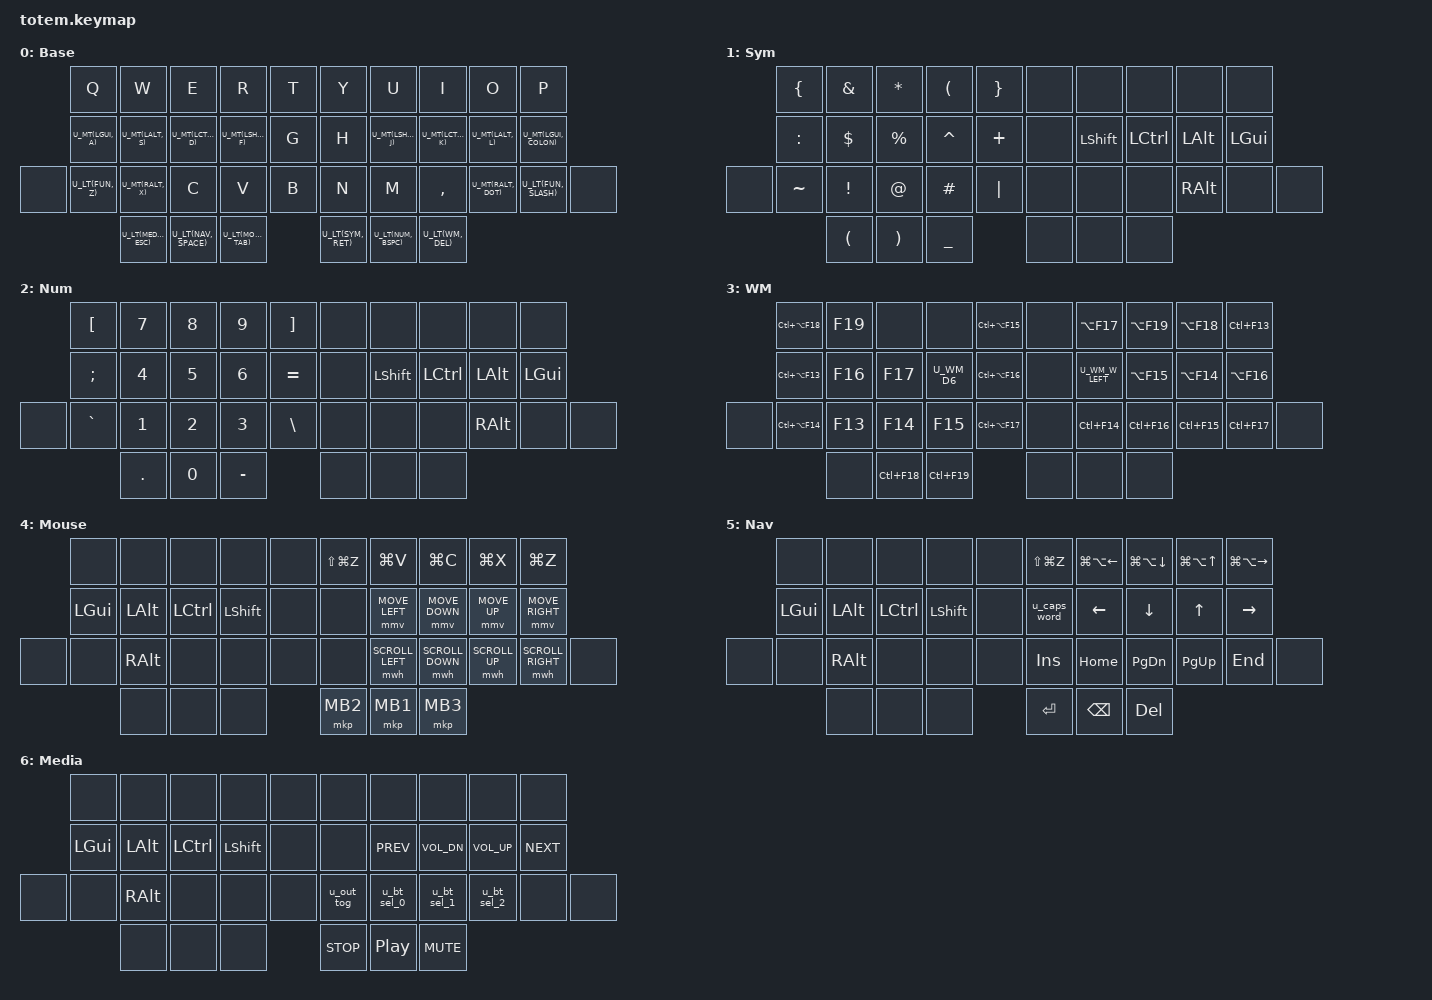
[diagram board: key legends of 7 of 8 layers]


#include <behaviors.dtsi>
#include <dt-bindings/zmk/keys.h>
#include <dt-bindings/zmk/bt.h>
#include <dt-bindings/zmk/outputs.h>
#include <dt-bindings/zmk/mouse.h>

// ⎯⎯⎯⎯⎯⎯⎯⎯⎯⎯⎯⎯⎯⎯⎯⎯⎯⎯⎯⎯⎯⎯⎯⎯⎯⎯⎯⎯⎯⎯⎯⎯⎯⎯⎯⎯⎯⎯⎯⎯⎯⎯⎯⎯⎯⎯⎯⎯⎯⎯⎯⎯⎯⎯⎯⎯⎯⎯⎯⎯⎯⎯⎯⎯⎯⎯⎯⎯⎯⎯⎯⎯⎯⎯⎯⎯⎯⎯⎯⎯⎯⎯⎯⎯⎯⎯⎯⎯⎯⎯

// Layers
#define BASE  0
#define SYM   1
#define NUM   2
#define WM    3
#define MOUSE 4
#define NAV   5
#define MEDIA 6
#define FUN   7

// Behaviors
#define U_NA &none
#define U_MT(MOD, TAP) &u_mt MOD TAP
#define U_LT(LAYER, TAP) &u_lt LAYER TAP

// Clipboard
#define U_RDO &kp LS(LG(Z))
#define U_PST &kp LG(V)
#define U_CPY &kp LG(C)
#define U_CUT &kp LG(X)
#define U_UND &kp LG(Z)

// Mouse key
#define U_MOUSE_MOVE_MAX 1250
#define U_MOUSE_MOVE_EXPONENT 1
#define U_MOUSE_MOVE_TIME 1500
#define U_MOUSE_MOVE_DELAY 0
#define U_MOUSE_SCROLL_MAX 100
#define U_MOUSE_SCROLL_EXPONENT 1
#define U_MOUSE_SCROLL_TIME 5000
#define U_MOUSE_SCROLL_DELAY 0

#undef MOVE_UP
#undef MOVE_DOWN
#undef MOVE_LEFT
#undef MOVE_RIGHT
#undef SCROLL_UP
#undef SCROLL_DOWN
#undef SCROLL_LEFT
#undef SCROLL_RIGHT
#define MOVE_UP MOVE_VERT(-U_MOUSE_MOVE_MAX)
#define MOVE_DOWN MOVE_VERT(U_MOUSE_MOVE_MAX)
#define MOVE_LEFT MOVE_HOR(-U_MOUSE_MOVE_MAX)
#define MOVE_RIGHT MOVE_HOR(U_MOUSE_MOVE_MAX)
#define SCROLL_UP SCROLL_VERT(U_MOUSE_SCROLL_MAX)
#define SCROLL_DOWN SCROLL_VERT(-U_MOUSE_SCROLL_MAX)
#define SCROLL_LEFT SCROLL_HOR(-U_MOUSE_SCROLL_MAX)
#define SCROLL_RIGHT SCROLL_HOR(U_MOUSE_SCROLL_MAX)

#define U_BTN1 &mkp MB1
#define U_BTN2 &mkp MB2
#define U_BTN3 &mkp MB3
#define U_MS_D &mmv MOVE_DOWN
#define U_MS_L &mmv MOVE_LEFT
#define U_MS_R &mmv MOVE_RIGHT
#define U_MS_U &mmv MOVE_UP
#define U_WH_D &mwh SCROLL_DOWN
#define U_WH_L &mwh SCROLL_LEFT
#define U_WH_R &mwh SCROLL_RIGHT
#define U_WH_U &mwh SCROLL_UP


&mmv {
  acceleration-exponent = <U_MOUSE_MOVE_EXPONENT>;
  time-to-max-speed-ms = <U_MOUSE_MOVE_TIME>;
  delay-ms = <U_MOUSE_MOVE_DELAY>;
};

// WM
#define U_WM_D1 &kp F13 // Focus to desktop 1
#define U_WM_D2 &kp F14 // Focus to desktop 2
#define U_WM_D3 &kp F15 // Focus to desktop 3
#define U_WM_D4 &kp F16 // Focus to desktop 4
#define U_WM_D5 &kp F17 // Focus to desktop 5
#define U_WM_D6 U_MT(LSHIFT, F18) // Focus to desktop 6
#define U_WM_D7 &kp F19 // Focus to desktop 7

#define U_WM_W_LEFT U_MT(LSHIFT, LA(F13)) // Focus to window left
#define U_WM_W_UP &kp LA(F14) // Focus to window up
#define U_WM_W_DOWN &kp LA(F15) // Focus to window down
#define U_WM_W_RIGHT &kp LA(F16) // Focus to window right

#define U_WM_DIS_LEFT &kp LA(F17) // Focus to display left
#define U_WM_DIS_UP &kp LA(F18) // Focus to display up
#define U_WM_DIS_DOWN &kp LA(F19) // Focus to display down
#define U_WM_DIS_RIGHT &kp LC(F13) // Focus to display right

#define U_WM_W_SIZE_LEFT &kp LC(F14) // Increase window size left
#define U_WM_W_SIZE_UP &kp LC(F15) // Increase window size up
#define U_WM_W_SIZE_DOWN &kp LC(F16) // Increase window size down
#define U_WM_W_SIZE_RIGHT &kp LC(F17) // Increase window size right

#define U_WM_D_LEFT &kp LC(F18) // Focus to previous desktop
#define U_WM_D_RIGHT &kp LC(F19) // Focus to next desktop

#define U_WM_X_MIRROR &kp LC(LA(F13)) // Mirror window horizontally
#define U_WM_Y_MIRROR &kp LC(LA(F14)) // Mirror window vertically
#define U_WM_W_ROTATE_CW &kp LC(LA(F15)) // Rotate window clockwise
#define U_WM_W_FLOAT_GRID &kp LC(LA(F16)) // Toggle window float/grid
#define U_WM_W_MAX &kp LC(LA(F17)) // Toggle window maximum
#define U_WM_W_BALANCE &kp LC(LA(F18)) // Toggle window maximum


#define U_TAPPING_TERM 200


/ {
    behaviors {
        u_mt: u_mt {
            compatible = "zmk,behavior-hold-tap";
            label = "u_mt";
            #binding-cells = <2>;
            tapping_term_ms = <U_TAPPING_TERM>;
            flavor = "tap-preferred";
            bindings = <&kp>, <&kp>;
        };
        u_lt: u_lt {
            compatible = "zmk,behavior-hold-tap";
            label = "u_lt";
            #binding-cells = <2>;
            tapping_term_ms = <U_TAPPING_TERM>;
            flavor = "tap-preferred";
            bindings = <&mo>, <&kp>;
        };

        // Shift functions
        u_caps_word: u_caps_word { 
            compatible = "zmk,behavior-mod-morph";
            label = "u_caps_word";
            #binding-cells = <0>;
            bindings = <&caps_word>, <&kp CAPS>;
            mods = <(MOD_LSFT|MOD_RSFT)>;
        };
        u_out_tog: u_out_tog { 
            compatible = "zmk,behavior-mod-morph";
            label = "u_out_tog";
            #binding-cells = <0>;
            bindings = <&out OUT_TOG>, <&out OUT_USB>;
            mods = <(MOD_LSFT|MOD_RSFT)>;
        };
        u_bt_sel_0: u_bt_sel_0 { 
            compatible = "zmk,behavior-mod-morph";
            label = "u_bt_sel_0";
            #binding-cells = <0>;
            bindings = <&bt BT_SEL 0>, <&u_macro_u_bt_sel_0>;
            mods = <(MOD_LSFT|MOD_RSFT)>;
        };
        u_bt_sel_1: u_bt_sel_1 { 
            compatible = "zmk,behavior-mod-morph";
            label = "u_bt_sel_1";
            #binding-cells = <0>;
            bindings = <&bt BT_SEL 1>, <&u_macro_u_bt_sel_0>;
            mods = <(MOD_LSFT|MOD_RSFT)>;
        };
        u_bt_sel_2: u_bt_sel_2 { 
            compatible = "zmk,behavior-mod-morph";
            label = "u_bt_sel_2";
            #binding-cells = <0>;
            bindings = <&bt BT_SEL 2>, <&u_macro_u_bt_sel_0>;
            mods = <(MOD_LSFT|MOD_RSFT)>;
        };
    };


    // combos {
    //     compatible = "zmk,combos";

    // };


    macros {
        u_macro_btn1: u_macro_btn1 {
            label = "u_macro_btn1";
            compatible = "zmk,behavior-macro";
            #binding-cells = <0>;
            wait-ms = <0>;
            bindings = <&kp KP_SLASH &kp KP_N5>;
        };

        u_macro_btn2: u_macro_btn2 {
            label = "u_macro_btn2";
            compatible = "zmk,behavior-macro";
            #binding-cells = <0>;
            wait-ms = <0>;
            bindings = <&kp KP_MINUS &kp KP_N5>;
        };

        u_macro_btn3: u_macro_btn3 {
            label = "u_macro_btn3";
            compatible = "zmk,behavior-macro";
            #binding-cells = <0>;
            wait-ms = <0>;
            bindings = <&kp KP_ASTERISK &kp KP_N5>;
        };

        u_macro_u_bt_sel_0: u_macro_u_bt_sel_0 {
            label = "u_macro_u_bt_sel_0";
            compatible = "zmk,behavior-macro";
            #binding-cells = <0>;
            wait-ms = <0>;
            bindings = <&bt BT_SEL 0 &bt BT_CLR>;
        };

        u_macro_u_bt_sel_1: u_macro_u_bt_sel_1 {
            label = "u_macro_u_bt_sel_1";
            compatible = "zmk,behavior-macro";
            #binding-cells = <0>;
            wait-ms = <0>;
            bindings = <&bt BT_SEL 1 &bt BT_CLR>;
        };

        u_macro_u_bt_sel_2: u_macro_u_bt_sel_2 {
            label = "u_macro_u_bt_sel_2";
            compatible = "zmk,behavior-macro";
            #binding-cells = <0>;
            wait-ms = <0>;
            bindings = <&bt BT_SEL 2 &bt BT_CLR>;
        };
    };


    keymap {
        compatible = "zmk,keymap";

        BASE {
            label= "Base";
            bindings = <
                &kp Q              &kp W             &kp E              &kp R              &kp T   /**/     &kp Y            &kp U             &kp I           &kp O             &kp P                
                U_MT(LGUI, A)      U_MT(LALT, S)     U_MT(LCTRL, D)     U_MT(LSHFT, F)     &kp G   /**/     &kp H            U_MT(LSHFT, J)    U_MT(LCTRL, K)  U_MT(LALT, L)     U_MT(LGUI, COLON)   
         U_NA   U_LT(FUN, Z)       U_MT(RALT, X)     &kp C              &kp V              &kp B   /**/     &kp N            &kp M             &kp COMMA       U_MT(RALT, DOT)   U_LT(FUN, SLASH) U_NA
                                        U_LT(MEDIA, ESC) U_LT(NAV, SPACE) U_LT(MOUSE, TAB)         /**/     U_LT(SYM, RET) U_LT(NUM, BSPC) U_LT(WM, DEL)
            >;
        };

        SYM {
            label= "Sym";
            bindings = <
                &kp LBRC          &kp AMPS         &kp ASTRK        &kp LPAR         &kp RBRC    /**/     U_NA             &none       &none    &none      U_NA
                &kp COLON         &kp DLLR         &kp PRCNT        &kp CARET        &kp PLUS    /**/     U_NA             &kp LSHFT          &kp LCTRL        &kp LALT         &kp LGUI
         U_NA   &kp TILDE         &kp EXCL         &kp AT           &kp HASH         &kp PIPE    /**/     U_NA             &none        &none    &kp RALT         U_NA      U_NA
                                                   &kp LPAR         &kp RPAR         &kp UNDER   /**/     U_NA             U_NA               U_NA
            >;
        };

        //         &kp SEMI          &kp N4          &kp N5          &kp N6          &kp EQUAL      /**/     U_NA             &kp LSHFT          &kp LCTRL        &kp LALT         &kp LGUI
        //  U_NA   &kp GRAVE         &kp N1          &kp N2          &kp N3          &kp BSLH       /**/     U_NA             &none        &none      &kp RALT         U_NA  U_NA
        //       
 
        NUM {
            label= "Num";
            bindings = <
                &kp LBKT          &kp N7          &kp N8          &kp N9          &kp RBKT       /**/     U_NA             &none       &none    &none      U_NA
                &kp SEMI          &kp N4          &kp N5          &kp N6          &kp EQUAL      /**/     U_NA             &kp LSHFT          &kp LCTRL        &kp LALT         &kp LGUI
         U_NA   &kp GRAVE         &kp N1          &kp N2          &kp N3          &kp BSLH       /**/     U_NA             &none        &none      &kp RALT         U_NA  U_NA
                                                  &kp DOT         &kp N0          &kp MINUS      /**/     U_NA             U_NA               U_NA
            >;
        };       

        WM {
            label= "WM";
            bindings = <
                 U_WM_W_BALANCE    U_WM_D7       U_NA      U_NA            U_WM_W_ROTATE_CW   /**/     U_NA    U_WM_DIS_LEFT       U_WM_DIS_DOWN     U_WM_DIS_UP      U_WM_DIS_RIGHT
                 U_WM_X_MIRROR     U_WM_D4       U_WM_D5   U_WM_D6         U_WM_W_FLOAT_GRID  /**/     U_NA    U_WM_W_LEFT         U_WM_W_DOWN       U_WM_W_UP        U_WM_W_RIGHT
         U_NA    U_WM_Y_MIRROR     U_WM_D1       U_WM_D2   U_WM_D3         U_WM_W_MAX         /**/     U_NA    U_WM_W_SIZE_LEFT    U_WM_W_SIZE_DOWN   U_WM_W_SIZE_UP   U_WM_W_SIZE_RIGHT     U_NA
                                       U_NA             U_WM_D_LEFT         U_WM_D_RIGHT      /**/     U_NA             U_NA               U_NA
            >;
        };   

        MOUSE {
            label= "Mouse";
            bindings = <
                &none            &none            &none           &none           &none   /**/    U_RDO        U_PST          U_CPY            U_CUT         U_UND
                &kp LGUI         &kp LALT         &kp LCTRL       &kp LSHFT       &none   /**/    &none        U_MS_L         U_MS_D           U_MS_U        U_MS_R
        U_NA    &none            &kp RALT         &none           &none           &none   /**/    &none        U_WH_L         U_WH_D           U_WH_U        U_WH_R   U_NA
                                                        &none      &none      &none       /**/    U_BTN2       U_BTN1         U_BTN3
            >;
        };


        NAV {
            label= "Nav";
            bindings = <
                &none             &none           &none            &none            U_NA        /**/     U_RDO             &kp LG(LA(LEFT_ARROW))  &kp LG(LA(DOWN_ARROW))  &kp LG(LA(UP_ARROW)) &kp LG(LA(RIGHT_ARROW))
                &kp LGUI          &kp LALT        &kp LCTRL        &kp LSHFT        U_NA        /**/     &u_caps_word      &kp LEFT             &kp DOWN             &kp UP            &kp RIGHT
        U_NA    U_NA              &kp RALT        &none            &none            U_NA        /**/     &kp INS           &kp HOME             &kp PG_DN            &kp PG_UP         &kp END  U_NA
                                                  U_NA             U_NA             U_NA        /**/     &kp RET           &kp BSPC             &kp DEL
            >;
        };

        MEDIA {
            label= "Media";
            bindings = <
                &none             &none            &none            &none           U_NA        /**/     &none            &none            &none            &none            &none
                &kp LGUI          &kp LALT         &kp LCTRL        &kp LSHFT       U_NA        /**/     &none            &kp C_PREV        &kp C_VOL_DN      &kp C_VOL_UP   &kp C_NEXT
        U_NA    U_NA              &kp RALT         &none            &none           U_NA        /**/     &u_out_tog       &u_bt_sel_0       &u_bt_sel_1       &u_bt_sel_2    U_NA U_NA
                                                             U_NA   U_NA            U_NA        /**/     &kp C_STOP       &kp C_PP          &kp C_MUTE
            >;
        };

        FUN {
            label= "Fun";
            bindings = <
                &kp F12           &kp F7           &kp F8           &kp F9           &kp PSCRN       /**/     U_NA             &none       &none    &none      &none
                &kp F11           &kp F4           &kp F5           &kp F6           &kp SLCK        /**/     U_NA             &kp LSHFT          &kp LCTRL        &kp LALT         &kp LGUI
        U_NA    &kp F10           &kp F1           &kp F2           &kp F3           &kp PAUSE_BREAK /**/     U_NA             &none        &none    &kp RALT         U_NA   U_NA
                                                   &kp K_APP        &kp SPACE        &kp TAB         /**/     U_NA             U_NA               U_NA             U_NA
            >;
        };
    };
};
